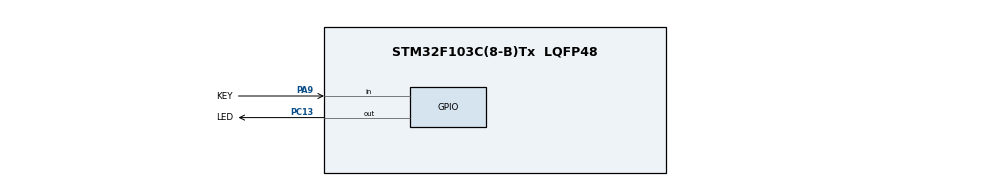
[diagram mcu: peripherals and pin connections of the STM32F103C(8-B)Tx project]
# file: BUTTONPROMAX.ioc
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Mcu.Family=STM32F1
Mcu.Name=STM32F103C(8-B)Tx
Mcu.Package=LQFP48
NVIC.PriorityGroup=NVIC_PRIORITYGROUP_4
NVIC.TIM2_IRQn=true\:0\:0\:false\:false\:true\:true\:true\:true
PA13.Mode=Serial_Wire
PA13.Signal=SYS_JTMS-SWDIO
PA14.Mode=Serial_Wire
PA14.Signal=SYS_JTCK-SWCLK
PA9.GPIO_Label=KEY
PA9.GPIO_PuPd=GPIO_PULLUP
PA9.Signal=GPIO_Input
PC13-TAMPER-RTC.GPIO_Label=LED
PC13-TAMPER-RTC.GPIO_ModeDefaultOutputPP=GPIO_MODE_OUTPUT_OD
PC13-TAMPER-RTC.GPIO_PuPd=GPIO_NOPULL
PC13-TAMPER-RTC.Signal=GPIO_Output
ProjectManager.HeapSize=0x200
ProjectManager.StackSize=0x400
ProjectManager.TargetToolchain=MDK-ARM V5.32
RCC.APB1Freq_Value=8000000
RCC.APB2Freq_Value=8000000
TIM2.AutoReloadPreload=TIM_AUTORELOAD_PRELOAD_DISABLE
TIM2.Period=999
TIM2.Prescaler=7
VP_TIM2_VS_ClockSourceINT.Mode=Internal
board=custom

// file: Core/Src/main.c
/* USER CODE BEGIN Header */
/**
  ******************************************************************************
  * @file           : main.c
  * @brief          : Main program body
  ******************************************************************************
  * @attention
  *
  * Copyright (c) 2026 STMicroelectronics.
  * All rights reserved.
  *
  * This software is licensed under terms that can be found in the LICENSE file
  * in the root directory of this software component.
  * If no LICENSE file comes with this software, it is provided AS-IS.
  *
  ******************************************************************************
  */
/* USER CODE END Header */
#include "main.h"

/* USER CODE BEGIN PD */
#define KEY_DEBOUNCE_MS   20u
#define KEY_LONG_MS     1000u
#define BLINK_HALF_MS    100u
/* USER CODE END PD */

TIM_HandleTypeDef htim2;

/* USER CODE BEGIN PV */
volatile uint8_t  key_cnt;
volatile uint8_t  key_pressed;
volatile uint8_t  key_released;

static uint8_t  led_on;
static uint8_t  blink_mode;
static uint32_t press_tick;
static uint32_t blink_tick;
/* USER CODE END PV */

void SystemClock_Config(void);
static void MX_GPIO_Init(void);
static void MX_TIM2_Init(void);
/* USER CODE BEGIN PFP */
static void LED_Write(uint8_t on);
/* USER CODE END PFP */

int main(void)
{

  /* MCU Configuration--------------------------------------------------------*/

  /* Reset of all peripherals, Initializes the Flash interface and the Systick. */
  HAL_Init();

  /* Configure the system clock */
  SystemClock_Config();

  /* Initialize all configured peripherals */
  MX_GPIO_Init();
  MX_TIM2_Init();
  /* USER CODE BEGIN 2 */
  led_on     = 0;
  blink_mode = 0;
  press_tick = 0;
  blink_tick = 0;

  LED_Write(0);

  HAL_TIM_Base_Start_IT(&htim2);
  /* USER CODE END 2 */

  /* Infinite loop */
  /* USER CODE BEGIN WHILE */
  while (1)
  {
    if (key_pressed != 0u)
    {
      key_pressed = 0u;
      press_tick  = HAL_GetTick();
    }

    if (key_released != 0u)
    {
      key_released = 0u;

      if ((HAL_GetTick() - press_tick) >= KEY_LONG_MS)
      {
        if (blink_mode == 0u)
        {
          blink_mode = 1u;
        }
        else
        {
          blink_mode = 0u;
        }
        blink_tick = HAL_GetTick();
        LED_Write(led_on);
      }
      else
      {
        blink_mode = 0u;
        if (led_on == 0u)
        {
          led_on = 1u;
        }
        else
        {
          led_on = 0u;
        }
        LED_Write(led_on);
      }
    }

    if ((blink_mode != 0u) && ((HAL_GetTick() - blink_tick) >= BLINK_HALF_MS))
    {
      blink_tick = HAL_GetTick();
      HAL_GPIO_TogglePin(LED_GPIO_Port, LED_Pin);
    }

    /* USER CODE END WHILE */

  }
}

void SystemClock_Config(void)
{
  RCC_OscInitTypeDef RCC_OscInitStruct = {0};
  RCC_ClkInitTypeDef RCC_ClkInitStruct = {0};

  /** Initializes the RCC Oscillators according to the specified parameters
  * in the RCC_OscInitTypeDef structure.
  */
  RCC_OscInitStruct.OscillatorType = RCC_OSCILLATORTYPE_HSI;
  RCC_OscInitStruct.HSIState = RCC_HSI_ON;
  RCC_OscInitStruct.HSICalibrationValue = RCC_HSICALIBRATION_DEFAULT;
  RCC_OscInitStruct.PLL.PLLState = RCC_PLL_NONE;
  if (HAL_RCC_OscConfig(&RCC_OscInitStruct) != HAL_OK)
  {
    Error_Handler();
  }

  /** Initializes the CPU, AHB and APB buses clocks
  */
  RCC_ClkInitStruct.ClockType = RCC_CLOCKTYPE_HCLK|RCC_CLOCKTYPE_SYSCLK
                              |RCC_CLOCKTYPE_PCLK1|RCC_CLOCKTYPE_PCLK2;
  RCC_ClkInitStruct.SYSCLKSource = RCC_SYSCLKSOURCE_HSI;
  RCC_ClkInitStruct.AHBCLKDivider = RCC_SYSCLK_DIV1;
  RCC_ClkInitStruct.APB1CLKDivider = RCC_HCLK_DIV1;
  RCC_ClkInitStruct.APB2CLKDivider = RCC_HCLK_DIV1;

  if (HAL_RCC_ClockConfig(&RCC_ClkInitStruct, FLASH_LATENCY_0) != HAL_OK)
  {
    Error_Handler();
  }
}

static void MX_TIM2_Init(void)
{

  TIM_ClockConfigTypeDef sClockSourceConfig = {0};
  TIM_MasterConfigTypeDef sMasterConfig = {0};

  htim2.Instance = TIM2;
  htim2.Init.Prescaler = 7;
  htim2.Init.CounterMode = TIM_COUNTERMODE_UP;
  htim2.Init.Period = 999;
  htim2.Init.ClockDivision = TIM_CLOCKDIVISION_DIV1;
  htim2.Init.AutoReloadPreload = TIM_AUTORELOAD_PRELOAD_DISABLE;
  if (HAL_TIM_Base_Init(&htim2) != HAL_OK)
  {
    Error_Handler();
  }
  sClockSourceConfig.ClockSource = TIM_CLOCKSOURCE_INTERNAL;
  if (HAL_TIM_ConfigClockSource(&htim2, &sClockSourceConfig) != HAL_OK)
  {
    Error_Handler();
  }
  sMasterConfig.MasterOutputTrigger = TIM_TRGO_RESET;
  sMasterConfig.MasterSlaveMode = TIM_MASTERSLAVEMODE_DISABLE;
  if (HAL_TIMEx_MasterConfigSynchronization(&htim2, &sMasterConfig) != HAL_OK)
  {
    Error_Handler();
  }

}

static void MX_GPIO_Init(void)
{
  GPIO_InitTypeDef GPIO_InitStruct = {0};

  /* GPIO Ports Clock Enable */
  __HAL_RCC_GPIOC_CLK_ENABLE();
  __HAL_RCC_GPIOA_CLK_ENABLE();

  /*Configure GPIO pin Output Level */
  HAL_GPIO_WritePin(LED_GPIO_Port, LED_Pin, GPIO_PIN_RESET);

  /*Configure GPIO pin : LED_Pin */
  GPIO_InitStruct.Pin = LED_Pin;
  GPIO_InitStruct.Mode = GPIO_MODE_OUTPUT_OD;
  GPIO_InitStruct.Pull = GPIO_NOPULL;
  GPIO_InitStruct.Speed = GPIO_SPEED_FREQ_LOW;
  HAL_GPIO_Init(LED_GPIO_Port, &GPIO_InitStruct);

  /*Configure GPIO pin : KEY_Pin */
  GPIO_InitStruct.Pin = KEY_Pin;
  GPIO_InitStruct.Mode = GPIO_MODE_INPUT;
  GPIO_InitStruct.Pull = GPIO_PULLUP;
  HAL_GPIO_Init(KEY_GPIO_Port, &GPIO_InitStruct);

}

/* USER CODE BEGIN 4 */
static void LED_Write(uint8_t on)
{
  if (on != 0u)
  {
    HAL_GPIO_WritePin(LED_GPIO_Port, LED_Pin, GPIO_PIN_RESET);
  }
  else
  {
    HAL_GPIO_WritePin(LED_GPIO_Port, LED_Pin, GPIO_PIN_SET);
  }
}

void HAL_TIM_PeriodElapsedCallback(TIM_HandleTypeDef *htim)
{
  if (htim->Instance != TIM2)
  {
    return;
  }

  if (HAL_GPIO_ReadPin(KEY_GPIO_Port, KEY_Pin) == GPIO_PIN_RESET)
  {
    if (key_cnt < KEY_DEBOUNCE_MS)
    {
      key_cnt++;
      if (key_cnt == KEY_DEBOUNCE_MS)
      {
        key_pressed = 1u;
      }
    }
  }
  else
  {
    if (key_cnt == KEY_DEBOUNCE_MS)
    {
      key_released = 1u;
    }
    key_cnt = 0;
  }
}
/* USER CODE END 4 */

void Error_Handler(void)
{
  __disable_irq();
  while (1)
  {
  }
}
